# AT32L021xx_v2 register map
Vendor: Keil; Series: AT32L021; File version: 1.0
CPU: CM0+ r0p1, little endian, MPU, no FPU, 4 interrupt priority bits
Registers are 32-bit, read-write, reset 0x0 unless marked. A register's access mark holds for its fields unless they carry their own. Offsets are from the block's base; [hi:lo] are bit positions; {n}, {i} and the like mark numbered series; 'fields as' and 'values as' point back to an identical list.

## DMA1 — DMA controller
Base 0x40020000
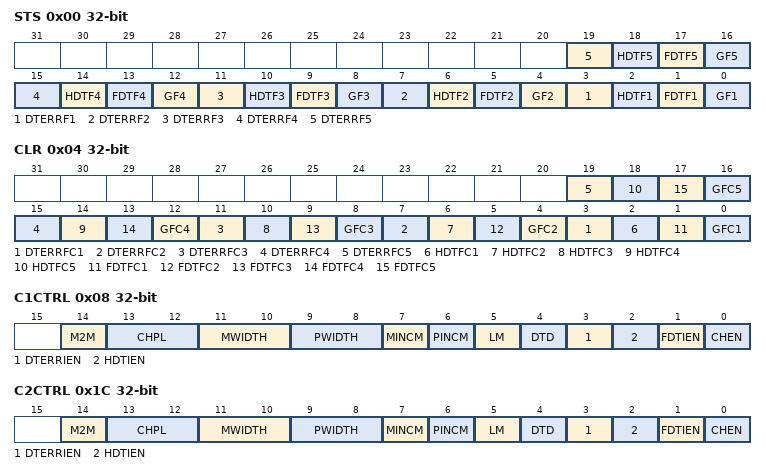
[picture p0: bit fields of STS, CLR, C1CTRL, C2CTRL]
0x00 STS ro — DMA status register (DMA_STS)
  [4n-1] DTERRF{n} (n=1..5) — Channel {n} data transfer error event flag
  [4n-2] HDTF{n} (n=1..5) — Channel {n} half data transfer event flag
  [4n-3] FDTF{n} (n=1..5) — Channel {n} full data transfer event flag
  [4n-4] GF{n} (n=1..5) — Channel {n} Global event flag
0x04 CLR — DMA flag clear register (DMA_CLR)
  [4n-1] DTERRFC{n} (n=1..5) — Channel {n} data transfer error flag clear
  [4n-2] HDTFC{n} (n=1..5) — Channel {n} half data transfer flag clear
  [4n-3] FDTFC{n} (n=1..5) — Channel {n} full data transfer flag clear
  [4n-4] GFC{n} (n=1..5) — Channel {n} Global flag clear
0x08 C1CTRL — DMA channel configuration register
  [14] M2M — Memory to memory mode
  [13:12] CHPL — Channel Priority level
  [11:10] MWIDTH — Memory data bit width
  [9:8] PWIDTH — Peripheral data bit width
  [7] MINCM — Memory address increment mode
  [6] PINCM — Peripheral address increment mode
  [5] LM — Loop mode
  [4] DTD — Data transfer direction
  [3] DTERRIEN — Data transfer error interrupt enable
  [2] HDTIEN — Half data transfer interrupt enable
  [1] FDTIEN — Full data transfer interrupt enable
  [0] CHEN — Channel enable
0x0C C1DTCNT — DMA channel 1 number of data to transfer register
  [15:0] CNT — Number of data to transfer
0x10 C1PADDR — DMA channel 1 peripheral base address register
  [31:0] PADDR — Peripheral address
{0x0+0x14*i} C{i}MADDR (i=1..5) — DMA channel {i} memory base address register
  [31:0] MADDR — Memory address
0x1C C2CTRL — DMA channel configuration register
  fields as C1CTRL
0x20 C2DTCNT — DMA channel 2 number of data to transfer register
  [15:0] CNT — Number of data to transfer
0x24 C2PADDR — DMA channel 2 peripheral base address register
  [31:0] PADDR — Peripheral address
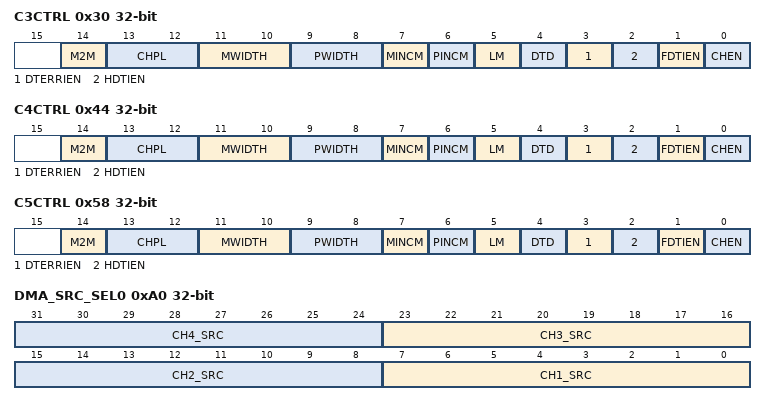
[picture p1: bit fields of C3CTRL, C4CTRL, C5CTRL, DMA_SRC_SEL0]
0x30 C3CTRL — DMA channel configuration register
  fields as C1CTRL
0x34 C3DTCNT — DMA channel 3 number of data to transfer register
  [15:0] CNT — Number of data to transfer
0x38 C3PADDR — DMA channel 3 peripheral base address register
  [31:0] PADDR — Peripheral address
0x44 C4CTRL — DMA channel configuration register
  fields as C1CTRL
0x48 C4DTCNT — DMA channel 4 number of data to transfer register
  [15:0] CNT — Number of data to transfer
0x4C C4PADDR — DMA channel 4 peripheral base address register
  [31:0] PADDR — Peripheral address
0x58 C5CTRL — DMA channel configuration register
  fields as C1CTRL
0x5C C5DTCNT — DMA channel 5 number of data to transfer register
  [15:0] CNT — Number of data to transfer
0x60 C5PADDR — DMA channel 5 peripheral base address register
  [31:0] PADDR — Peripheral address
0xA0 DMA_SRC_SEL0 — DMA channel source assignment register
  [8n-1:8n-8] CH{n}_SRC (n=1..4) — CH{n} SRC select
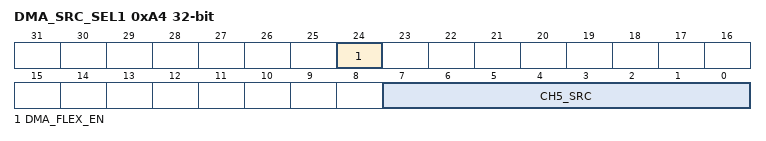
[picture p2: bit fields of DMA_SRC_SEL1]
0xA4 DMA_SRC_SEL1 — DMA channel source assignment register
  [24] DMA_FLEX_EN — DMA FLEX Enable
  [7:0] CH5_SRC — CH5 SRC select

## WDT — Watchdog
Base 0x40003000
0x00 CMD wo — Command register
  [15:0] CMD
0x04 DIV — Division register
  [2:0] DIV — Division divider
0x08 RLD reset 0xFFF — Reload register
  [11:0] RLD — Reload value
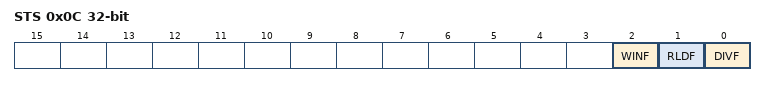
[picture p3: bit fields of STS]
0x0C STS ro — Status register
  [2] WINF — Window value update complete flag
  [1] RLDF — Reload value update complete flag
  [0] DIVF — Division value update complete flag
0x10 WIN reset 0xFFF — Window register
  [11:0] WIN — Window value

## WWDT — Window watchdog
Base 0x40002C00
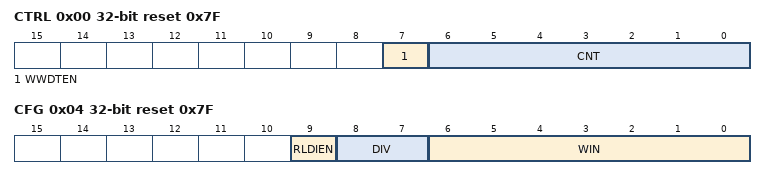
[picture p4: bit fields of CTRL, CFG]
0x00 CTRL reset 0x7F — Control register
  [7] WWDTEN — Window watchdog enable
  [6:0] CNT — Decrement counter
0x04 CFG reset 0x7F — Configuration register
  [9] RLDIEN — Reload counter interrupt
  [8:7] DIV — Clock division value
  [6:0] WIN — Window value
0x08 STS — Status register
  [0] RLDF — Reload counter interrupt flag
